# DSC28027 register map
Vendor: Beijing Haawking Technology Co.,Ltd.; File version: 1.0
Registers are 32-bit, read-write, reset 0x0 unless marked. A register's access mark holds for its fields unless they carry their own. Offsets are from the block's base; [hi:lo] are bit positions; lines under a group give offsets from that group; {n}, {i} and the like mark numbered series; 'fields as' and 'values as' point back to an identical list.

## I2S0 — Inter-Integrated Sound Interface 0
Base 0x50250000
Same registers: I2S1 0x50260000, I2S2 0x50270000
0x00 ier — Enable Register
  [0] ien — I2S Enable
0x04 irer — Receiver Block Enable Register
  [0] rxen — Receiver block enable
0x08 iter — Transmitter Block Enable Register
  [0] txen — Transmitter block enable
0x0C cer — Clock Generation enable
  [0] clken — Transmitter block enable
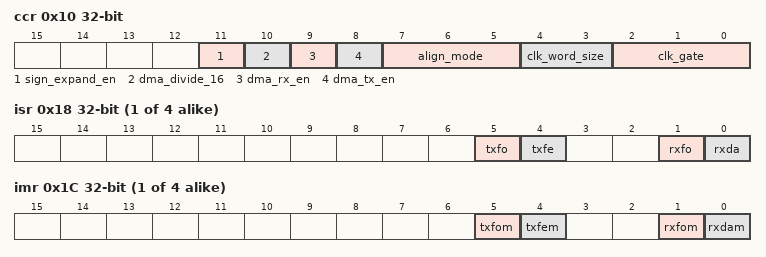
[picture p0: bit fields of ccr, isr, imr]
0x10 ccr — Clock Configuration Register
  [11] sign_expand_en
  [10] dma_divide_16 — Split 32bit data to two 16 bit data and filled in left and right channel. Used with dma_tx_en or dma_rx_en
  [9] dma_rx_en — DMA receive enable control
  [8] dma_tx_en — DMA transmit enable control
  [7:5] align_mode — Alignment mode setting
    1=Standard I2S format; 2=Right aligned format; 4=Left aligned format
  [4:3] clk_word_size — The number of sclk cycles for which the word select line stayd in the left aligned or right aligned mode
    0=cycles16 (16 sclk cycles); 1=cycles24 (24 sclk cycles); 2=cycles32 (32 sclk cycles)
  [2:0] clk_gate — Gating of sclk
    0=no (Clock gating is disabled); 1=cycles12 (Gating after 12 sclk cycles); 2=cycles16 (Gating after 16 sclk cycles); 3=cycles20 (Gating after 20 sclk cycles); 4=cycles24 (Gating after 24 sclk cycles)
0x14 rxffr — Receiver Block FIFO Reset Register
  [0] rxffr — Receiver FIFO reset
    0=Not flush FIFO; 1=Flush FIFO
0x18 txffr — Transmitter Block FIFO Reset Register
  [0] rxffr — Transmitter FIFO reset
    0=Not flush FIFO; 1=Flush FIFO
{0x20+0x40*i} channel{i} (i=0..3) group — Channel cluster
  0x00 left_rxtx — Left Receive or Left Transmit Register
  0x04 right_rxtx — Right Receive or Right Transmit Register
  0x08 rer — Receive Enable Register
    [0] rxchenx — Receive channel enable/disable
  0x0C ter — Transmit Enable Register
    [0] txchenx — Transmit channel enable/disable
  0x10 rcr — Receive Configuration Register
    [2:0] wlen — Desired data resolution of receiver
      0=Ignore the word length; 1=resolution12 (12-bit data resolution of the receiver); 2=resolution16 (16-bit data resolution of the receiver); 3=resolution20 (20-bit data resolution of the receiver); 4=resolution24 (24-bit data resolution of the receiver); 5=resolution32 (32-bit data resolution of the receiver)
  0x14 tcr — Transmit Configuration Register
    [2:0] wlen — Desired data resolution of transmitter
      values as channel0.rcr.wlen
  0x18 isr ro — Interrupt Status Register
    [5] txfo — Status of data overrun interrupt for the TX channel
    [4] txfe — Status of transmit empty triger interrupt
    [1] rxfo — Status of data overrun interrupt for RX channel
    [0] rxda — Status of receiver data avaliable interrupt
  0x1C imr — Interrupt Mask Register
    [5] txfom — Mask TX FIFO overrun interrupt
    [4] txfem — Mask TX FIFO empty interrupt
    [1] rxfom — Mask RX FIFO overrun interrupt
    [0] rxdam — Mask RX FIFO data avaliable interrupt
  0x20 ror ro — Receive Overrun Register
    [0] rxcho — Read this bit to clear RX FIFO data overrun interrupt. 0x0 for RX FIFO write valid, 0x1 for RX FIFO write overrun
  0x24 tor ro — Transmit Overrun Register
    [0] txcho — Read this bit to clear TX FIFO data overrun interrupt. 0x0 for TX FIFO write valid, 0x1 for TX FIFO write overrun
  0x28 rfcr — Receive FIFO Configuration Register
    [3:0] rxchdt — Trigger level in the RX FIFO at which the receiver data available interrupt generate
      {v}=level{v+1} (Interrupt trigger when FIFO level is {v+1}) (v=0..15)
  0x2C tfcr — Transmit FIFO Configuration Register
    [3:0] txchet — Trigger level in the TX FIFO at which the transmitter data available interrupt generate
      values as channel0.rfcr.rxchdt
  0x30 rff — Receive FIFO Flush Register
    [0] rxchfr — Receiver channel FIFO reset
      0=Not flush an individual FIFO; 1=Flush an indiviadual FIFO
  0x34 tff — Transmit FIFO Flush Register
    [0] rtxchfr — Transmit channel FIFO reset
      0=Not flush an individual FIFO; 1=Flush an indiviadual FIFO
  {0x38+4j} _reserved{j} (j=0..1) — _RESERVED0
0x1C0 rxdma — Receiver Block DMA Register
0x1C4 rrxdma — Reset Receiver Block DMA Register
0x1C8 txdma — Transmitter Block DMA Register
0x1CC rtxdma — Reset Transmitter Block DMA Register
0x1F0 i2s_comp_param_2 — Component Parameter Register 2
0x1F4 i2s_comp_param_1 — Component Parameter Register 1
0x1F8 i2s_comp_version_1 — Component Version Register
0x1FC i2s_comp_type — Component Type Register
